# ATSAMC21J18AU device description
Architecture: CORTEX-M0PLUS; Family: SAMC; Series: SAMC21
Registers are 32-bit, read-write, reset 0x0 unless marked. A register's access mark holds for its fields unless they carry their own. Offsets are from the block's base; [hi:lo] are bit positions; lines under a group give offsets from that group; {n}, {i} and the like mark numbered series.

## GCLK — Generic Clock Generator
Instances: GCLK 0x40001C00
0x00 CTRLA 8-bit (WSYNC) — Control
  [0] SWRST — Software Reset
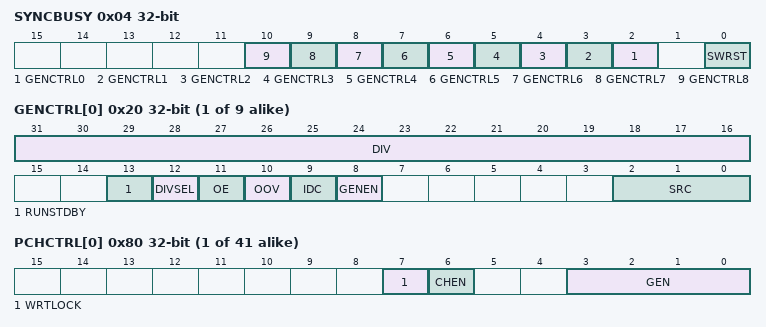
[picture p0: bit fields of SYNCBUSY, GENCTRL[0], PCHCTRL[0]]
0x04 SYNCBUSY ro — Synchronization Busy
  [n+2] GENCTRL{n} (n=0..8) — Generic Clock Generator Control {n} Synchronization Busy bits
    1=GCLK0 (Generic clock generator 0); 2=GCLK1 (Generic clock generator 1); 4=GCLK2 (Generic clock generator 2); 8=GCLK3 (Generic clock generator 3); 16=GCLK4 (Generic clock generator 4); 32=GCLK5 (Generic clock generator 5); 64=GCLK6 (Generic clock generator 6); 128=GCLK7 (Generic clock generator 7); 0x100=GCLK8 (Generic clock generator 8)
  [0] SWRST — Software Reset Synchroniation Busy bit
{0x20+4i} GENCTRL[{i}] (i=0..8) — Generic Clock Generator Control
  [31:16] DIV — Division Factor
  [13] RUNSTDBY — Run in Standby
  [12] DIVSEL — Divide Selection
    0=DIV1 (Divide input directly by divider factor); 1=DIV2 (Divide input by 2^(divider factor+ 1))
  [11] OE — Output Enable
  [10] OOV — Output Off Value
  [9] IDC — Improve Duty Cycle
  [8] GENEN — Generic Clock Generator Enable
  [2:0] SRC — Source Select
    0=XOSC (XOSC oscillator output); 1=GCLKIN (Generator input pad); 2=GCLKGEN1 (Generic clock generator 1 output); 3=OSCULP32K (OSCULP32K oscillator output); 4=OSC32K (OSC32K oscillator output); 5=XOSC32K (XOSC32K oscillator output); 6=OSC48M (OSC48M oscillator output); 7=DPLL96M (DPLL96M output)
{0x80+4i} PCHCTRL[{i}] (i=0..40) — Peripheral Clock Control
  [7] WRTLOCK — Write Lock
  [6] CHEN — Channel Enable
  [3:0] GEN — Generic Clock Generator
    {v}=GCLK{v} (Generic clock generator {v}) (v=0..8)

## HMATRIXB — HSB Matrix
Instances: HMATRIXHS 0x4100A000
{0x0+4i} MCFG[{i}] (i=0..15) reset 0x2 — Master Configuration
  [2:0] ULBT — Undefined Length Burst Type
    0=INFINITE (Infinite Length); 1=SINGLE (Single Access); 2=FOUR_BEAT (Four Beat Burst); 3=EIGHT_BEAT (Eight Beat Burst); 4=SIXTEEN_BEAT (Sixteen Beat Burst)
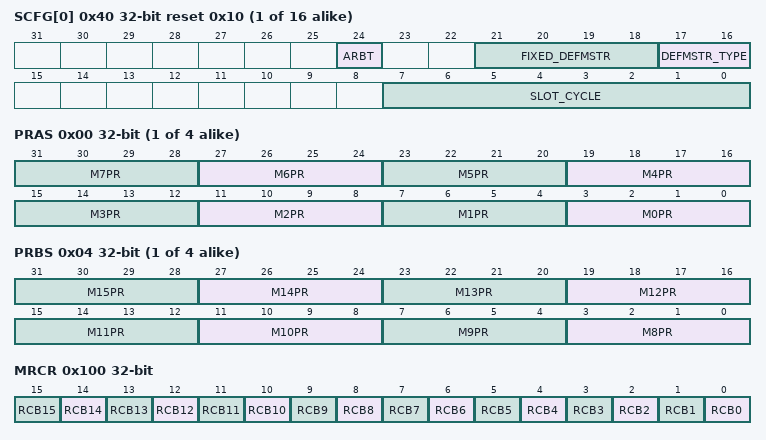
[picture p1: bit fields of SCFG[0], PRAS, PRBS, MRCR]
{0x40+4i} SCFG[{i}] (i=0..15) reset 0x10 — Slave Configuration
  [24] ARBT — Arbitration Type
    0=ROUND_ROBIN (Round-Robin Arbitration); 1=FIXED_PRIORITY (Fixed Priority Arbitration)
  [21:18] FIXED_DEFMSTR — Fixed Index of Default Master
  [17:16] DEFMSTR_TYPE — Default Master Type
    0=NO_DEFAULT (No Default Master. At the end of current slave access, if no other master request is pending, the slave is deconnected from all masters. This resusts in having a one cycle latency for the first transfer of a burst.); 1=LAST_DEFAULT (Last Default Master At the end of current slave access, if no other master request is pending, the slave stay connected with the last master havingaccessed it.This resusts in not having the one cycle latency when the last master re-trying access on the slave.); 2=FIXED_DEFAULT (Fixed Default Master At the end of current slave access, if no other master request is pending, the slave connects with fixed master which numberis in FIXED_DEFMSTR register.This resusts in not having the one cycle latency when the fixed master re-trying access on the slave.)
  [7:0] SLOT_CYCLE — Maximum Number of Allowed Cycles for a Burst
{0x80+8i} PRS[{i}] (i=0..3) group
  0x00 PRAS — Priority A for Slave
    [4n+3:4n] M{n}PR (n=0..7) — Master {n} Priority
  0x04 PRBS — Priority B for Slave
    [4n-29:4n-32] M{n}PR (n=8..15) — Master {n} Priority
0x100 MRCR — Master Remap Control
  [all] fields
    0=DIS (Disable remapped address decoding for master); 1=ENA (Enable remapped address decoding for master)
  [n] RCB{n} (n=0..15) — Remap Command Bit for Master {n}
{0x110+4i} SFR[{i}] (i=0..15) — Special Function
  [31:0] SFR — Special Function Register

## MCLK — Main Clock
Instances: MCLK 0x40000800
0x01 INTENCLR 8-bit (atomic clear) — Interrupt Enable Clear
  [0] CKRDY — Clock Ready Interrupt Enable
0x02 INTENSET 8-bit (atomic set) — Interrupt Enable Set
  [0] CKRDY — Clock Ready Interrupt Enable
0x03 INTFLAG 8-bit reset 0x1 (atomic clear) — Interrupt Flag Status and Clear
  [0] CKRDY — Clock Ready
0x04 CPUDIV 8-bit reset 0x1 — CPU Clock Division
  [7:0] CPUDIV — CPU Clock Division Factor
    1=DIV1 (Divide by 1); 2=DIV2 (Divide by 2); 4=DIV4 (Divide by 4); 8=DIV8 (Divide by 8); 16=DIV16 (Divide by 16); 32=DIV32 (Divide by 32); 64=DIV64 (Divide by 64); 128=DIV128 (Divide by 128)
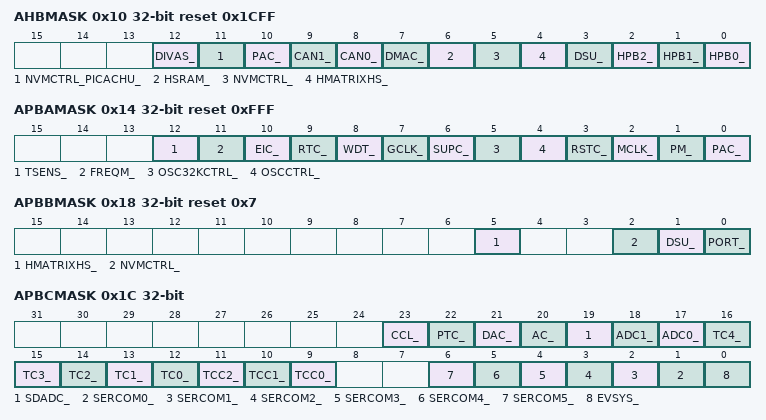
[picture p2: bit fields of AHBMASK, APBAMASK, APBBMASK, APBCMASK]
0x10 AHBMASK reset 0x1CFF
  [12] DIVAS_ — DIVAS AHB Clock Mask
  [11] NVMCTRL_PICACHU_ — NVMCTRL_PICACHU AHB Clock Mask
  [10] PAC_ — PAC AHB Clock Mask
  [9] CAN1_ — CAN1 AHB Clock Mask
  [8] CAN0_ — CAN0 AHB Clock Mask
  [7] DMAC_ — DMAC AHB Clock Mask
  [6] HSRAM_ — HSRAM AHB Clock Mask
  [5] NVMCTRL_ — NVMCTRL AHB Clock Mask
  [4] HMATRIXHS_ — HMATRIXHS AHB Clock Mask
  [3] DSU_ — DSU AHB Clock Mask
  [2] HPB2_ — HPB2 AHB Clock Mask
  [1] HPB1_ — HPB1 AHB Clock Mask
  [0] HPB0_ — HPB0 AHB Clock Mask
0x14 APBAMASK reset 0xFFF
  [12] TSENS_ — TSENS APB Clock Enable
  [11] FREQM_ — FREQM APB Clock Enable
  [10] EIC_ — EIC APB Clock Enable
  [9] RTC_ — RTC APB Clock Enable
  [8] WDT_ — WDT APB Clock Enable
  [7] GCLK_ — GCLK APB Clock Enable
  [6] SUPC_ — SUPC APB Clock Enable
  [5] OSC32KCTRL_ — OSC32KCTRL APB Clock Enable
  [4] OSCCTRL_ — OSCCTRL APB Clock Enable
  [3] RSTC_ — RSTC APB Clock Enable
  [2] MCLK_ — MCLK APB Clock Enable
  [1] PM_ — PM APB Clock Enable
  [0] PAC_ — PAC APB Clock Enable
0x18 APBBMASK reset 0x7
  [5] HMATRIXHS_ — HMATRIXHS APB Clock Enable
  [2] NVMCTRL_ — NVMCTRL APB Clock Enable
  [1] DSU_ — DSU APB Clock Enable
  [0] PORT_ — PORT APB Clock Enable
0x1C APBCMASK
  [23] CCL_ — CCL APB Clock Enable
  [22] PTC_ — PTC APB Clock Enable
  [21] DAC_ — DAC APB Clock Enable
  [20] AC_ — AC APB Clock Enable
  [19] SDADC_ — SDADC APB Clock Enable
  [18] ADC1_ — ADC1 APB Clock Enable
  [17] ADC0_ — ADC0 APB Clock Enable
  [n+12] TC{n}_ (n=0..4) — TC{n} APB Clock Enable
  [11] TCC2_ — TCC2 APB Clock Enable
  [10] TCC1_ — TCC1 APB Clock Enable
  [9] TCC0_ — TCC0 APB Clock Enable
  [n+1] SERCOM{n}_ (n=0..5) — SERCOM{n} APB Clock Enable
  [0] EVSYS_ — EVSYS APB Clock Enable

## Notices in the file
Copyright (c) 2018 Microchip Technology Inc.
SPDX-License-Identifier: Apache-2.0
Licensed under the Apache License, Version 2.0 (the "License");
you may not use this file except in compliance with the License.
You may obtain a copy of the License at
http://www.apache.org/licenses/LICENSE-2.0
Unless required by applicable law or agreed to in writing, software
distributed under the License is distributed on an "AS IS" BASIS,
WITHOUT WARRANTIES OR CONDITIONS OF ANY KIND, either express or implied.
See the License for the specific language governing permissions and
limitations under the License.
